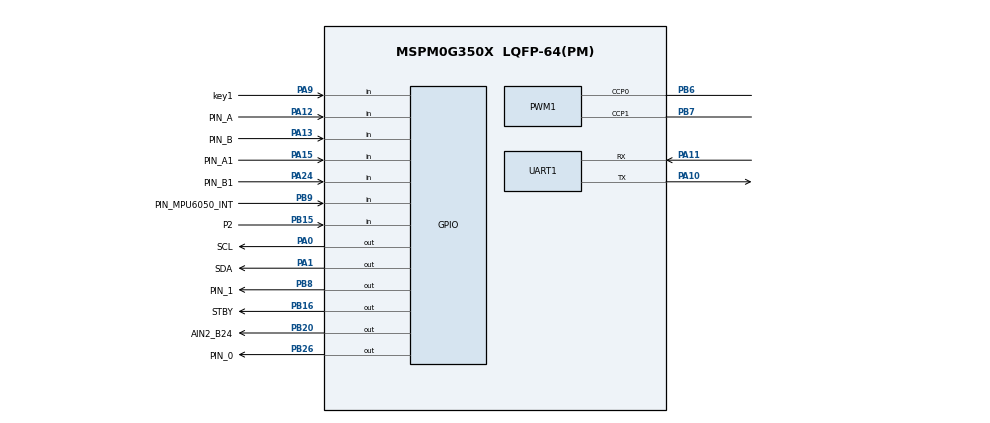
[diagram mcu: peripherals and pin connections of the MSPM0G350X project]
/**
 * @cliArgs --device "MSPM0G350X" --part "Default" --package "LQFP-64(PM)" --product "mspm0_sdk@2.05.01.01"
 * @versions {"tool":"1.24.0+4110"}
 */

/**
 * Import the modules used in this configuration.
 */
const GPIO   = scripting.addModule("/ti/driverlib/GPIO", {}, false);
const GPIO1  = GPIO.addInstance();
const GPIO2  = GPIO.addInstance();
const GPIO3  = GPIO.addInstance();
const GPIO4  = GPIO.addInstance();
const GPIO5  = GPIO.addInstance();
const GPIO6  = GPIO.addInstance();
const GPIO7  = GPIO.addInstance();
const GPIO8  = GPIO.addInstance();
const PWM    = scripting.addModule("/ti/driverlib/PWM", {}, false);
const PWM1   = PWM.addInstance();
const SYSCTL = scripting.addModule("/ti/driverlib/SYSCTL");
const TIMER  = scripting.addModule("/ti/driverlib/TIMER", {}, false);
const TIMER1 = TIMER.addInstance();
const UART   = scripting.addModule("/ti/driverlib/UART", {}, false);
const UART1  = UART.addInstance();

/**
 * Write custom configuration values to the imported modules.
 */
const divider6       = system.clockTree["PLL_CLK2X_DIV"];
divider6.divideValue = 4;

const divider7       = system.clockTree["PLL_PDIV"];
divider7.divideValue = 2;

const divider9       = system.clockTree["UDIV"];
divider9.divideValue = 2;

const gate7  = system.clockTree["MFCLKGATE"];
gate7.enable = true;

const multiplier2         = system.clockTree["PLL_QDIV"];
multiplier2.multiplyValue = 10;

const mux8       = system.clockTree["HSCLKMUX"];
mux8.inputSelect = "HSCLKMUX_SYSPLL2X";

GPIO1.$name                          = "TRACK";
GPIO1.associatedPins.create(8);
GPIO1.associatedPins[0].direction    = "INPUT";
GPIO1.associatedPins[0].assignedPort = "PORTA";
GPIO1.associatedPins[0].assignedPin  = "28";
GPIO1.associatedPins[0].$name        = "P4";
GPIO1.associatedPins[1].direction    = "INPUT";
GPIO1.associatedPins[1].assignedPort = "PORTB";
GPIO1.associatedPins[1].assignedPin  = "1";
GPIO1.associatedPins[1].$name        = "P5";
GPIO1.associatedPins[2].direction    = "INPUT";
GPIO1.associatedPins[2].assignedPort = "PORTB";
GPIO1.associatedPins[2].assignedPin  = "4";
GPIO1.associatedPins[2].$name        = "P6";
GPIO1.associatedPins[3].direction    = "INPUT";
GPIO1.associatedPins[3].assignedPort = "PORTB";
GPIO1.associatedPins[3].assignedPin  = "17";
GPIO1.associatedPins[3].$name        = "P7";
GPIO1.associatedPins[4].direction    = "INPUT";
GPIO1.associatedPins[4].assignedPort = "PORTB";
GPIO1.associatedPins[4].assignedPin  = "12";
GPIO1.associatedPins[4].$name        = "P8";
GPIO1.associatedPins[5].$name        = "P3";
GPIO1.associatedPins[5].direction    = "INPUT";
GPIO1.associatedPins[5].assignedPort = "PORTA";
GPIO1.associatedPins[5].assignedPin  = "31";
GPIO1.associatedPins[6].$name        = "P2";
GPIO1.associatedPins[6].direction    = "INPUT";
GPIO1.associatedPins[6].pin.$assign  = "PB15";
GPIO1.associatedPins[7].$name        = "P1";
GPIO1.associatedPins[7].direction    = "INPUT";
GPIO1.associatedPins[7].assignedPort = "PORTB";
GPIO1.associatedPins[7].assignedPin  = "13";

const Board = scripting.addModule("/ti/driverlib/Board", {}, false);

GPIO2.$name                          = "MOTOR";
GPIO2.associatedPins.create(5);
GPIO2.associatedPins[0].$name        = "AIN1_A02";
GPIO2.associatedPins[0].assignedPort = "PORTB";
GPIO2.associatedPins[0].assignedPin  = "24";
GPIO2.associatedPins[1].$name        = "AIN2_B24";
GPIO2.associatedPins[1].assignedPort = "PORTB";
GPIO2.associatedPins[1].assignedPin  = "20";
GPIO2.associatedPins[1].pin.$assign  = "PB20";
GPIO2.associatedPins[2].$name        = "BIN1_B20";
GPIO2.associatedPins[2].assignedPort = "PORTB";
GPIO2.associatedPins[2].assignedPin  = "18";
GPIO2.associatedPins[3].$name        = "BIN2_B19";
GPIO2.associatedPins[3].assignedPort = "PORTB";
GPIO2.associatedPins[3].assignedPin  = "19";
GPIO2.associatedPins[4].$name        = "STBY";
GPIO2.associatedPins[4].assignedPort = "PORTB";
GPIO2.associatedPins[4].assignedPin  = "16";
GPIO2.associatedPins[4].pin.$assign  = "PB16";

GPIO3.$name                          = "KEY";
GPIO3.associatedPins.create(2);
GPIO3.associatedPins[0].$name        = "key1";
GPIO3.associatedPins[0].direction    = "INPUT";
GPIO3.associatedPins[0].assignedPort = "PORTA";
GPIO3.associatedPins[0].assignedPin  = "9";
GPIO3.associatedPins[0].pin.$assign  = "PA9";
GPIO3.associatedPins[1].$name        = "key2";
GPIO3.associatedPins[1].direction    = "INPUT";
GPIO3.associatedPins[1].assignedPort = "PORTA";
GPIO3.associatedPins[1].assignedPin  = "8";

GPIO4.$name                               = "GPIO_ENCODER";
GPIO4.associatedPins.create(4);
GPIO4.associatedPins[0].$name             = "PIN_A";
GPIO4.associatedPins[0].direction         = "INPUT";
GPIO4.associatedPins[0].interruptEn       = true;
GPIO4.associatedPins[0].interruptPriority = "0";
GPIO4.associatedPins[0].polarity          = "RISE";
GPIO4.associatedPins[0].internalResistor  = "PULL_UP";
GPIO4.associatedPins[0].assignedPort      = "PORTA";
GPIO4.associatedPins[0].assignedPin       = "12";
GPIO4.associatedPins[0].pin.$assign       = "PA12";
GPIO4.associatedPins[1].$name             = "PIN_B";
GPIO4.associatedPins[1].direction         = "INPUT";
GPIO4.associatedPins[1].interruptEn       = true;
GPIO4.associatedPins[1].interruptPriority = "0";
GPIO4.associatedPins[1].polarity          = "RISE";
GPIO4.associatedPins[1].internalResistor  = "PULL_UP";
GPIO4.associatedPins[1].assignedPin       = "13";
GPIO4.associatedPins[1].assignedPort      = "PORTA";
GPIO4.associatedPins[1].pin.$assign       = "PA13";
GPIO4.associatedPins[2].$name             = "PIN_A1";
GPIO4.associatedPins[2].direction         = "INPUT";
GPIO4.associatedPins[2].polarity          = "RISE";
GPIO4.associatedPins[2].interruptEn       = true;
GPIO4.associatedPins[2].interruptPriority = "0";
GPIO4.associatedPins[2].internalResistor  = "PULL_UP";
GPIO4.associatedPins[2].assignedPort      = "PORTA";
GPIO4.associatedPins[2].assignedPin       = "15";
GPIO4.associatedPins[2].pin.$assign       = "PA15";
GPIO4.associatedPins[3].$name             = "PIN_B1";
GPIO4.associatedPins[3].direction         = "INPUT";
GPIO4.associatedPins[3].interruptEn       = true;
GPIO4.associatedPins[3].interruptPriority = "0";
GPIO4.associatedPins[3].polarity          = "RISE";
GPIO4.associatedPins[3].internalResistor  = "PULL_UP";
GPIO4.associatedPins[3].assignedPort      = "PORTA";
GPIO4.associatedPins[3].assignedPin       = "24";
GPIO4.associatedPins[3].pin.$assign       = "PA24";

GPIO5.$name                          = "LED";
GPIO5.associatedPins[0].$name        = "PIN_0";
GPIO5.associatedPins[0].assignedPort = "PORTB";
GPIO5.associatedPins[0].assignedPin  = "26";
GPIO5.associatedPins[0].pin.$assign  = "PB26";

GPIO6.$name                         = "BUUZER";
GPIO6.port                          = "PORTB";
GPIO6.associatedPins[0].$name       = "PIN_1";
GPIO6.associatedPins[0].assignedPin = "8";
GPIO6.associatedPins[0].pin.$assign = "PB8";

GPIO7.$name                               = "GPIO_MPU6050";
GPIO7.associatedPins[0].$name             = "PIN_MPU6050_INT";
GPIO7.associatedPins[0].direction         = "INPUT";
GPIO7.associatedPins[0].internalResistor  = "PULL_UP";
GPIO7.associatedPins[0].polarity          = "FALL";
GPIO7.associatedPins[0].interruptEn       = true;
GPIO7.associatedPins[0].interruptPriority = "1";
GPIO7.associatedPins[0].pin.$assign       = "PB9";

GPIO8.$name                          = "GPIO";
GPIO8.associatedPins.create(2);
GPIO8.associatedPins[0].$name        = "SCL";
GPIO8.associatedPins[0].initialValue = "SET";
GPIO8.associatedPins[0].ioStructure  = "OD";
GPIO8.associatedPins[0].assignedPort = "PORTA";
GPIO8.associatedPins[0].assignedPin  = "0";
GPIO8.associatedPins[0].pin.$assign  = "PA0";
GPIO8.associatedPins[1].$name        = "SDA";
GPIO8.associatedPins[1].initialValue = "SET";
GPIO8.associatedPins[1].ioStructure  = "OD";
GPIO8.associatedPins[1].assignedPort = "PORTA";
GPIO8.associatedPins[1].assignedPin  = "1";
GPIO8.associatedPins[1].pin.$assign  = "PA1";

PWM1.$name                              = "PWM_MOTOR";
PWM1.timerStartTimer                    = true;
PWM1.peripheral.$assign                 = "TIMG6";
PWM1.peripheral.ccp0Pin.$assign         = "PB6";
PWM1.peripheral.ccp1Pin.$assign         = "PB7";
PWM1.PWM_CHANNEL_0.$name                = "ti_driverlib_pwm_PWMTimerCC0";
PWM1.PWM_CHANNEL_0.invert               = true;
PWM1.PWM_CHANNEL_1.$name                = "ti_driverlib_pwm_PWMTimerCC1";
PWM1.PWM_CHANNEL_1.invert               = true;
PWM1.ccp0PinConfig.direction            = scripting.forceWrite("OUTPUT");
PWM1.ccp0PinConfig.hideOutputInversion  = scripting.forceWrite(false);
PWM1.ccp0PinConfig.onlyInternalResistor = scripting.forceWrite(false);
PWM1.ccp0PinConfig.passedPeripheralType = scripting.forceWrite("Digital");
PWM1.ccp0PinConfig.$name                = "ti_driverlib_gpio_GPIOPinGeneric2";
PWM1.ccp1PinConfig.direction            = scripting.forceWrite("OUTPUT");
PWM1.ccp1PinConfig.hideOutputInversion  = scripting.forceWrite(false);
PWM1.ccp1PinConfig.onlyInternalResistor = scripting.forceWrite(false);
PWM1.ccp1PinConfig.passedPeripheralType = scripting.forceWrite("Digital");
PWM1.ccp1PinConfig.$name                = "ti_driverlib_gpio_GPIOPinGeneric3";

SYSCTL.forceDefaultClkConfig = true;
SYSCTL.clockTreeEn           = true;

TIMER1.$name              = "TIMER_0";
TIMER1.timerClkPrescale   = 200;
TIMER1.timerStartTimer    = true;
TIMER1.timerMode          = "PERIODIC";
TIMER1.interrupts         = ["ZERO"];
TIMER1.interruptPriority  = "3";
TIMER1.timerClkDiv        = 2;
TIMER1.timerPeriod        = "10ms";
TIMER1.peripheral.$assign = "TIMA0";

UART1.$name                    = "UART_0";
UART1.uartClkSrc               = "MFCLK";
UART1.enabledInterrupts        = ["RX"];
UART1.enableFIFO               = true;
UART1.peripheral.$assign       = "UART0";
UART1.peripheral.rxPin.$assign = "PA11";
UART1.peripheral.txPin.$assign = "PA10";
UART1.txPinConfig.$name        = "ti_driverlib_gpio_GPIOPinGeneric0";
UART1.rxPinConfig.$name        = "ti_driverlib_gpio_GPIOPinGeneric1";

/**
 * Pinmux solution for unlocked pins/peripherals. This ensures that minor changes to the automatic solver in a future
 * version of the tool will not impact the pinmux you originally saw.  These lines can be completely deleted in order to
 * re-solve from scratch.
 */
GPIO1.associatedPins[0].pin.$suggestSolution = "PA28";
GPIO1.associatedPins[1].pin.$suggestSolution = "PB1";
GPIO1.associatedPins[2].pin.$suggestSolution = "PB4";
GPIO1.associatedPins[3].pin.$suggestSolution = "PB17";
GPIO1.associatedPins[4].pin.$suggestSolution = "PB12";
GPIO1.associatedPins[5].pin.$suggestSolution = "PA31";
GPIO1.associatedPins[7].pin.$suggestSolution = "PB13";
Board.peripheral.$suggestSolution            = "DEBUGSS";
Board.peripheral.swclkPin.$suggestSolution   = "PA20";
Board.peripheral.swdioPin.$suggestSolution   = "PA19";
GPIO2.associatedPins[0].pin.$suggestSolution = "PB24";
GPIO2.associatedPins[2].pin.$suggestSolution = "PB18";
GPIO2.associatedPins[3].pin.$suggestSolution = "PB19";
GPIO3.associatedPins[1].pin.$suggestSolution = "PA8";
